# STM8AF6269 register map
Vendor: STMicroelectronics; Series: STM8S/STM8AF, medium density; File version: 1.0
CPU: other r1p0, big endian, no MPU, no FPU, 4 interrupt priority bits
Registers are 8-bit, read-write, reset 0x0 unless marked. A register's access mark holds for its fields unless they carry their own. Offsets are from the block's base; [hi:lo] are bit positions; {n}, {i} and the like mark numbered series.

## TIM2
Base 0x00005300
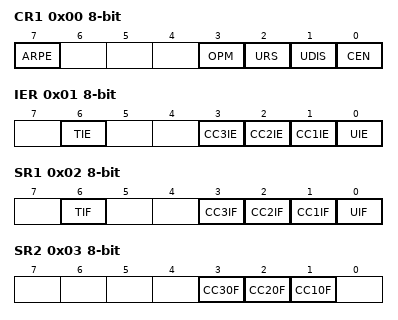
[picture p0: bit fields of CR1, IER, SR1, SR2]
0x00 CR1 — TIM2 control register 1
  [7] ARPE, [3] OPM, [2] URS, [1] UDIS, [0] CEN
0x01 IER — TIM2 interrupt enable register
  [6] TIE, [3] CC3IE, [2] CC2IE, [1] CC1IE, [0] UIE
0x02 SR1 — TIM2 status register 1
  [6] TIF, [3] CC3IF, [2] CC2IF, [1] CC1IF, [0] UIF
0x03 SR2 — TIM2 status register 2
  [3] CC30F, [2] CC20F, [1] CC10F
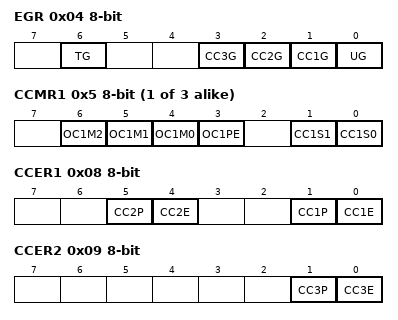
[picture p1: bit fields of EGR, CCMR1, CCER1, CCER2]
0x04 EGR — TIM2 event generation register
  [6] TG, [3] CC3G, [2] CC2G, [1] CC1G, [0] UG
{0x4+i} CCMR{i} (i=1..3) — TIM2 capture/compare mode register {i}
  [6] OC{i}M2, [5] OC{i}M1, [4] OC{i}M0, [3] OC{i}PE, [1] CC{i}S1, [0] CC{i}S0
0x08 CCER1 — TIM2 capture/compare enable register 1
  [5] CC2P, [4] CC2E, [1] CC1P, [0] CC1E
0x09 CCER2 — TIM2 capture/compare enable register 2
  [1] CC3P, [0] CC3E
0x0A CNTRH — TIM2 counter high
  [7:0] CNT
0x0B CNTRL — TIM2 counter low
  [7:0] CNT
0x0C PSCR — TIM2 prescaler register
  [3:0] PSC
0x0D ARRH reset 0xFF — TIM2 auto-reload register high
  [7:0] ARR
0x0E ARRL reset 0xFF — TIM2 auto-reload register low
  [7:0] ARR
0x0F CCR1H — TIM2 capture/compare register 1 high
  [7:0] CCR
0x10 CCR1L — TIM2 capture/compare register 1 low
  [7:0] CCR
0x11 CCR2H — TIM2 capture/compare register 2 high
  [7:0] CCR2
0x12 CCR2L — TIM2 capture/compare register 2 low
  [7:0] CCR2
0x13 CCR3H — TIM2 capture/compare register 3 high
  [7:0] CCR3
0x14 CCR3L — TIM2 capture/compare register 3 low
  [7:0] CCR3

## TIM3
Base 0x00005320
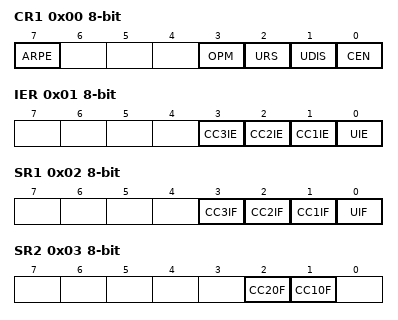
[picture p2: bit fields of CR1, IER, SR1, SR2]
0x00 CR1 — TIM3 control register 1
  [7] ARPE, [3] OPM, [2] URS, [1] UDIS, [0] CEN
0x01 IER — TIM3 interrupt enable register
  [3] CC3IE, [2] CC2IE, [1] CC1IE, [0] UIE
0x02 SR1 — TIM3 status register 1
  [3] CC3IF, [2] CC2IF, [1] CC1IF, [0] UIF
0x03 SR2 — TIM3 status register 2
  [2] CC20F, [1] CC10F
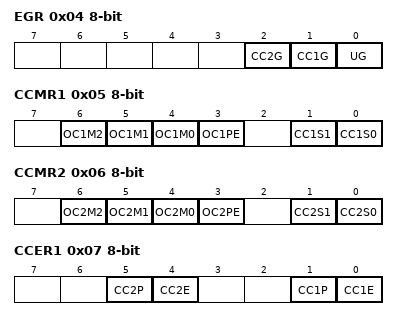
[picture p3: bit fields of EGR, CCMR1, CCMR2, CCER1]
0x04 EGR — TIM3 event generation register
  [2] CC2G, [1] CC1G, [0] UG
0x05 CCMR1 — TIM3 capture/compare mode register 1
  [6] OC1M2, [5] OC1M1, [4] OC1M0, [3] OC1PE, [1] CC1S1, [0] CC1S0
0x06 CCMR2 — TIM3 capture/compare mode register 2
  [6] OC2M2, [5] OC2M1, [4] OC2M0, [3] OC2PE, [1] CC2S1, [0] CC2S0
0x07 CCER1 — TIM3 capture/compare enable register 1
  [5] CC2P, [4] CC2E, [1] CC1P, [0] CC1E
0x08 CNTRH — TIM3 counter high
  [7:0] CNT
0x09 CNTRL — TIM3 counter low
  [7:0] CNT
0x0A PSCR — TIM3 prescaler register
  [3:0] PSC
0x0B ARRH reset 0xFF — TIM3 auto-reload register high
  [7:0] ARR
0x0C ARRL reset 0xFF — TIM3 auto-reload register low
  [7:0] ARR
0x0D CCR1H — TIM3 capture/compare register 1 high
  [7:0] CCR
0x0E CCR1L — TIM3 capture/compare register 1 low
  [7:0] CCR
0x0F CCR2H — TIM3 capture/compare register 2 high
  [7:0] CCR2
0x10 CCR2L — TIM3 capture/compare register 2 low
  [7:0] CCR2

## TIM4
Base 0x00005340
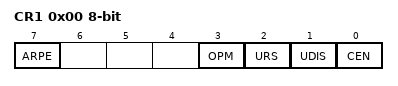
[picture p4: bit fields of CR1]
0x00 CR1 — TIM4 control register 1
  [7] ARPE, [3] OPM, [2] URS, [1] UDIS, [0] CEN
0x01 IER — TIM4 interrupt enable register
  [0] UIE
0x02 SR1 — TIM4 status register
  [0] UIF
0x03 EGR — TIM4 event generation register
  [0] UG
0x04 CNTR — TIM4 counter
  [7:0] CNT
0x05 PSCR — TIM4 prescaler register
  [2:0] PSC
0x06 ARR reset 0xFF — TIM4 auto-reload register

## TMU
Base 0x00005800
0x00 K1 — TMU key 1
  [7:0] K
0x01 K2 — TMU key 2
  [7:0] K
0x02 K3 — TMU key 3
  [7:0] K
0x03 K4 — TMU key 4
  [7:0] K
0x04 K5 — TMU key 5
  [7:0] K
0x05 K6 — TMU key 6
  [7:0] K
0x06 K7 — TMU key 7
  [7:0] K
0x07 K8 — TMU key 8
  [7:0] K
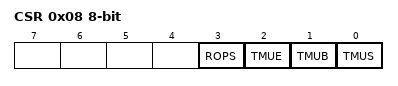
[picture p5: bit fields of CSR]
0x08 CSR — TMU status register
  [3] ROPS, [2] TMUE, [1] TMUB, [0] TMUS

## USART
Base 0x00005230
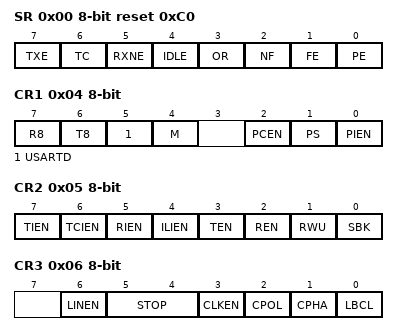
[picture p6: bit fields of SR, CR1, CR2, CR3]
0x00 SR reset 0xC0 — USART status register
  [7] TXE, [6] TC, [5] RXNE, [4] IDLE, [3] OR, [2] NF, [1] FE, [0] PE
0x01 DR — USART data register
0x02 BRR1 — USART baud rate register 1
  [7:0] USART_DIV
0x03 BRR2 — USART baud rate register 2
  [7:0] USART_DIV
0x04 CR1 — USART control register 1
  [7] R8, [6] T8, [5] USARTD, [4] M, [2] PCEN, [1] PS, [0] PIEN
0x05 CR2 — USART control register 2
  [7] TIEN, [6] TCIEN, [5] RIEN, [4] ILIEN, [3] TEN, [2] REN, [1] RWU, [0] SBK
0x06 CR3 — USART control register 3
  [6] LINEN, [5:4] STOP, [3] CLKEN, [2] CPOL, [1] CPHA, [0] LBCL
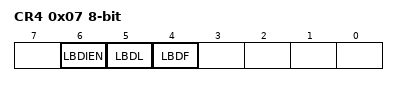
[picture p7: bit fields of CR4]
0x07 CR4 — USART control register 4
  [6] LBDIEN, [5] LBDL, [4] LBDF

## WWDG
Base 0x000050D1
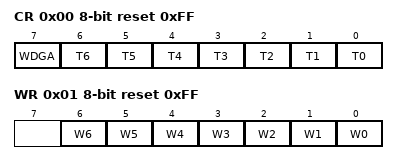
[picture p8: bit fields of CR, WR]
0x00 CR reset 0xFF — WWDG control register
  [7] WDGA, [n] T{n} (n=0..6)
0x01 WR reset 0xFF — WWDR window register
  [n] W{n} (n=0..6)
